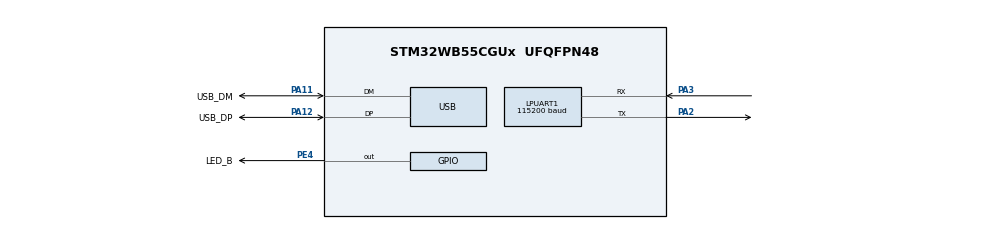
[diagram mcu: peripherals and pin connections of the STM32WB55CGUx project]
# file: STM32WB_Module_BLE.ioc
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Dma.LPUART1_RX.0.Direction=DMA_PERIPH_TO_MEMORY
Dma.LPUART1_RX.0.EventEnable=DISABLE
Dma.LPUART1_RX.0.Instance=DMA1_Channel1
Dma.LPUART1_RX.0.MemDataAlignment=DMA_MDATAALIGN_BYTE
Dma.LPUART1_RX.0.MemInc=DMA_MINC_ENABLE
Dma.LPUART1_RX.0.Mode=DMA_NORMAL
Dma.LPUART1_RX.0.PeriphDataAlignment=DMA_PDATAALIGN_BYTE
Dma.LPUART1_RX.0.PeriphInc=DMA_PINC_DISABLE
Dma.LPUART1_RX.0.Polarity=HAL_DMAMUX_REQ_GEN_RISING
Dma.LPUART1_RX.0.Priority=DMA_PRIORITY_MEDIUM
Dma.LPUART1_RX.0.RequestNumber=1
Dma.LPUART1_RX.0.SignalID=NONE
Dma.LPUART1_RX.0.SyncEnable=DISABLE
Dma.LPUART1_RX.0.SyncPolarity=HAL_DMAMUX_SYNC_NO_EVENT
Dma.LPUART1_RX.0.SyncRequestNumber=1
Dma.LPUART1_RX.0.SyncSignalID=NONE
Dma.LPUART1_TX.1.Direction=DMA_MEMORY_TO_PERIPH
Dma.LPUART1_TX.1.EventEnable=DISABLE
Dma.LPUART1_TX.1.Instance=DMA1_Channel2
Dma.LPUART1_TX.1.MemDataAlignment=DMA_MDATAALIGN_BYTE
Dma.LPUART1_TX.1.MemInc=DMA_MINC_ENABLE
Dma.LPUART1_TX.1.Mode=DMA_NORMAL
Dma.LPUART1_TX.1.PeriphDataAlignment=DMA_PDATAALIGN_BYTE
Dma.LPUART1_TX.1.PeriphInc=DMA_PINC_DISABLE
Dma.LPUART1_TX.1.Polarity=HAL_DMAMUX_REQ_GEN_RISING
Dma.LPUART1_TX.1.Priority=DMA_PRIORITY_MEDIUM
Dma.LPUART1_TX.1.RequestNumber=1
Dma.LPUART1_TX.1.SignalID=NONE
Dma.LPUART1_TX.1.SyncEnable=DISABLE
Dma.LPUART1_TX.1.SyncPolarity=HAL_DMAMUX_SYNC_NO_EVENT
Dma.LPUART1_TX.1.SyncRequestNumber=1
Dma.LPUART1_TX.1.SyncSignalID=NONE
Dma.Request0=LPUART1_RX
Dma.Request1=LPUART1_TX
LPUART1.BaudRate=115200
Mcu.Family=STM32WB
Mcu.Name=STM32WB55CGUx
Mcu.Package=UFQFPN48
NVIC.DMA1_Channel1_IRQn=true\:0\:0\:false\:false\:true\:false\:true\:true
NVIC.DMA1_Channel2_IRQn=true\:0\:0\:false\:false\:true\:false\:true\:true
NVIC.HSEM_IRQn=true\:0\:0\:false\:false\:true\:false\:true\:true
NVIC.IPCC_C1_RX_IRQn=true\:0\:0\:false\:false\:true\:true\:true\:true
NVIC.IPCC_C1_TX_IRQn=true\:0\:0\:false\:false\:true\:true\:true\:true
NVIC.LPUART1_IRQn=true\:0\:0\:false\:false\:true\:true\:true\:true
NVIC.PriorityGroup=NVIC_PRIORITYGROUP_4
NVIC.USB_HP_IRQn=true\:0\:0\:false\:false\:true\:true\:true\:true
NVIC.USB_LP_IRQn=true\:0\:0\:false\:false\:true\:false\:true\:true
OSC_IN.GPIO_Label=RCC_OSC_IN
OSC_IN.Mode=HSE-External-Oscillator
OSC_IN.Signal=RCC_OSC_IN
OSC_OUT.GPIO_Label=RCC_OSC_OUT
OSC_OUT.Mode=HSE-External-Oscillator
OSC_OUT.Signal=RCC_OSC_OUT
P-NUCLEO-WB55-USBDONGLE.BUTTON=1
P-NUCLEO-WB55-USBDONGLE.Bsp_Common_DEMO=true
P-NUCLEO-WB55-USBDONGLE.LD1=true
P-NUCLEO-WB55-USBDONGLE.LD2=true
P-NUCLEO-WB55-USBDONGLE.LD3=true
P-NUCLEO-WB55-USBDONGLE.VCP=false
PA11.GPIO_Label=USB_DM
PA11.Mode=Device
PA11.Signal=USB_DM
PA12.GPIO_Label=USB_DP
PA12.Mode=Device
PA12.Signal=USB_DP
PA13.GPIO_Label=JTMS
PA13.Signal=SYS_JTMS-SWDIO
PA14.GPIO_Label=JTCK
PA14.Signal=SYS_JTCK-SWCLK
PA2.Mode=Asynchronous
PA2.Signal=LPUART1_TX
PA3.Mode=Asynchronous
PA3.Signal=LPUART1_RX
PB3.GPIO_Label=JTDO
PB3.Signal=SYS_JTDO-SWO
PC14-OSC32_IN.GPIO_Label=RCC_OSC32_IN
PC14-OSC32_IN.Mode=LSE-External-Oscillator
PC14-OSC32_IN.Signal=RCC_OSC32_IN
PC15-OSC32_OUT.GPIO_Label=RCC_OSC32_OUT
PC15-OSC32_OUT.Mode=LSE-External-Oscillator
PC15-OSC32_OUT.Signal=RCC_OSC32_OUT
PE4.GPIO_Label=LED_B
PE4.Signal=GPIO_Output
ProjectManager.HeapSize=0x2000
ProjectManager.StackSize=0x4000
ProjectManager.TargetToolchain=CMake
RCC.ADCFreq_Value=48000000
RCC.AHB2CLKDivider=RCC_SYSCLK_DIV2
RCC.AHBFreq_Value=64000000
RCC.APB1Freq_Value=64000000
RCC.APB1TimFreq_Value=64000000
RCC.APB2Freq_Value=64000000
RCC.APB2TimFreq_Value=64000000
RCC.APB3Freq_Value=16000000
RCC.CK48CLockSelection=RCC_USBCLKSOURCE_PLL
RCC.CortexFreq_Value=64000000
RCC.HCLKFreq_Value=64000000
RCC.HSE_VALUE=32000000
RCC.HSI48_VALUE=48000000
RCC.HSI_VALUE=16000000
RCC.PLLN=48
RCC.PLLQ=RCC_PLLQ_DIV4
RCC.PLLR=RCC_PLLR_DIV3
RCC.PLLSAI1N=24
RCC.RTCClockSelection=RCC_RTCCLKSOURCE_LSE
RCC.SMPSDivider=1
RCC.SYSCLKFreq_VALUE=64000000
RCC.SYSCLKSource=RCC_SYSCLKSOURCE_PLLCLK
RCC.USBFreq_Value=48000000
RCC.VCOOutputFreq_Value=192000000
RF1.Mode=RF1_Activate
RF1.Signal=RF_RF1
STM32_WPAN.BLE_APPLICATION_TYPE=BLE_CLIENT_PROFILE
STM32_WPAN.CFG_BLE_NUM_LINK=8
STM32_WPAN.CFG_DEBUG_APP_TRACE=1
STM32_WPAN.CFG_DEBUG_TRACE_FULL=1
STM32_WPAN.CFG_DEBUG_TRACE_LIGHT=1
STM32_WPAN.CFG_DEBUG_TRACE_UART=hw_lpuart1
STM32_WPAN.CFG_HW_LPUART1_ENABLED=1
STM32_WPAN.CFG_LSCLK_LSE=0
USB_DEVICE.CLASS_NAME_FS=CDC
USB_DEVICE.VirtualMode=Cdc
USB_DEVICE.VirtualModeFS=Cdc_FS
VP_HSEM_VS_HSEM.Mode=HSEM_Activate
VP_IPCC_VS_IPCC.Mode=IPCC_Activate
VP_MEMORYMAP_VS_MEMORYMAP.Mode=CurAppReg
VP_RCC_USB.Mode=CRS SYNC Source USB
VP_RNG_VS_RNG.Mode=RNG_Activate
VP_RTC_VS_RTC_Activate.Mode=RTC_Enabled
VP_SEQUENCER_VS_SEQUENCER.Mode=SEQUENCER_Enabled
VP_STM32_WPAN_VS_BLE_HOST.Mode=STM32_WPAN_Enabled
VP_TINY_LPM_VS_TINY_LPM.Mode=TINY_LPM_Enabled
VP_USB_DEVICE_VS_USB_DEVICE_CDC_FS.Mode=CDC_FS
board=P-NUCLEO-WB55-USBDONGLE

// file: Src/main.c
/* USER CODE BEGIN Header */
/**
  ******************************************************************************
  * @file           : main.c
  * @brief          : Main program body
  ******************************************************************************
  * @attention
  *
  * Copyright (c) 2026 STMicroelectronics.
  * All rights reserved.
  *
  * This software is licensed under terms that can be found in the LICENSE file
  * in the root directory of this software component.
  * If no LICENSE file comes with this software, it is provided AS-IS.
  *
  ******************************************************************************
  */
/* USER CODE END Header */
#include "main.h"
#include "usb_device.h"

/* USER CODE BEGIN Includes */
#include "usbd_cdc_if.h"
#include "module_execute.h"
#include "at_command.h"
/* USER CODE END Includes */

IPCC_HandleTypeDef hipcc;

UART_HandleTypeDef hlpuart1;
DMA_HandleTypeDef hdma_lpuart1_rx;
DMA_HandleTypeDef hdma_lpuart1_tx;

RNG_HandleTypeDef hrng;

RTC_HandleTypeDef hrtc;

void SystemClock_Config(void);
void PeriphCommonClock_Config(void);
static void MX_GPIO_Init(void);
static void MX_DMA_Init(void);
static void MX_IPCC_Init(void);
static void MX_LPUART1_UART_Init(void);
static void MX_RTC_Init(void);
static void MX_RNG_Init(void);
static void MX_RF_Init(void);

/* USER CODE BEGIN 0 */
int _write(int file, char *ptr, int len)
{
  CDC_Transmit_FS((uint8_t *)ptr, len);
  // HAL_UART_Transmit(&hlpuart1, (uint8_t *)ptr, len, 0xFFFF);
  return len;
}
/* USER CODE END 0 */

int main(void)
{

  /* MCU Configuration--------------------------------------------------------*/

  /* Reset of all peripherals, Initializes the Flash interface and the Systick. */
  HAL_Init();
  /* Config code for STM32_WPAN (HSE Tuning must be done before system clock configuration) */
  MX_APPE_Config();

  /* Configure the system clock */
  SystemClock_Config();

  /* Configure the peripherals common clocks */
  PeriphCommonClock_Config();

  /* IPCC initialisation */
  MX_IPCC_Init();

  /* Initialize all configured peripherals */
  MX_GPIO_Init();
  MX_DMA_Init();
  MX_LPUART1_UART_Init();
  MX_RTC_Init();
  MX_RNG_Init();
  /* Init code for STM32_WPAN */
  MX_APPE_Init();
  HAL_Delay(100); // Delay to ensure BLE stack is properly initialized
  MX_USB_Device_Init();
  MX_RF_Init();
  /* USER CODE BEGIN 2 */
  printf("STM32WB55 BLE Gateway Starting...\r\n");
  HAL_GPIO_TogglePin(LED_B_GPIO_Port, LED_B_Pin);
  printf("Leds On\r\n");
  module_ble_init();
  printf("BLE Module Initialized\r\n");
  /* USER CODE END 2 */

  /* Infinite loop */
  while (1)
  {
    MX_APPE_Process();

  }
}

void SystemClock_Config(void)
{
  RCC_OscInitTypeDef RCC_OscInitStruct = {0};
  RCC_ClkInitTypeDef RCC_ClkInitStruct = {0};
  RCC_CRSInitTypeDef RCC_CRSInitStruct = {0};

  /** Configure LSE Drive Capability
  */
  HAL_PWR_EnableBkUpAccess();
  __HAL_RCC_LSEDRIVE_CONFIG(RCC_LSEDRIVE_MEDIUMHIGH);

  /** Configure the main internal regulator output voltage
  */
  __HAL_PWR_VOLTAGESCALING_CONFIG(PWR_REGULATOR_VOLTAGE_SCALE1);

  /** Initializes the RCC Oscillators according to the specified parameters
  * in the RCC_OscInitTypeDef structure.
  */
  RCC_OscInitStruct.OscillatorType = RCC_OSCILLATORTYPE_HSI|RCC_OSCILLATORTYPE_LSI1
                              |RCC_OSCILLATORTYPE_HSE|RCC_OSCILLATORTYPE_LSE
                              |RCC_OSCILLATORTYPE_MSI;
  RCC_OscInitStruct.HSEState = RCC_HSE_ON;
  RCC_OscInitStruct.LSEState = RCC_LSE_ON;
  RCC_OscInitStruct.HSIState = RCC_HSI_ON;
  RCC_OscInitStruct.MSIState = RCC_MSI_ON;
  RCC_OscInitStruct.HSICalibrationValue = RCC_HSICALIBRATION_DEFAULT;
  RCC_OscInitStruct.MSICalibrationValue = RCC_MSICALIBRATION_DEFAULT;
  RCC_OscInitStruct.MSIClockRange = RCC_MSIRANGE_6;
  RCC_OscInitStruct.LSIState = RCC_LSI_ON;
  RCC_OscInitStruct.PLL.PLLState = RCC_PLL_ON;
  RCC_OscInitStruct.PLL.PLLSource = RCC_PLLSOURCE_MSI;
  RCC_OscInitStruct.PLL.PLLM = RCC_PLLM_DIV1;
  RCC_OscInitStruct.PLL.PLLN = 48;
  RCC_OscInitStruct.PLL.PLLP = RCC_PLLP_DIV2;
  RCC_OscInitStruct.PLL.PLLR = RCC_PLLR_DIV3;
  RCC_OscInitStruct.PLL.PLLQ = RCC_PLLQ_DIV4;
  if (HAL_RCC_OscConfig(&RCC_OscInitStruct) != HAL_OK)
  {
    Error_Handler();
  }

  /** Configure the SYSCLKSource, HCLK, PCLK1 and PCLK2 clocks dividers
  */
  RCC_ClkInitStruct.ClockType = RCC_CLOCKTYPE_HCLK4|RCC_CLOCKTYPE_HCLK2
                              |RCC_CLOCKTYPE_HCLK|RCC_CLOCKTYPE_SYSCLK
                              |RCC_CLOCKTYPE_PCLK1|RCC_CLOCKTYPE_PCLK2;
  RCC_ClkInitStruct.SYSCLKSource = RCC_SYSCLKSOURCE_PLLCLK;
  RCC_ClkInitStruct.AHBCLKDivider = RCC_SYSCLK_DIV1;
  RCC_ClkInitStruct.APB1CLKDivider = RCC_HCLK_DIV1;
  RCC_ClkInitStruct.APB2CLKDivider = RCC_HCLK_DIV1;
  RCC_ClkInitStruct.AHBCLK2Divider = RCC_SYSCLK_DIV2;
  RCC_ClkInitStruct.AHBCLK4Divider = RCC_SYSCLK_DIV1;

  if (HAL_RCC_ClockConfig(&RCC_ClkInitStruct, FLASH_LATENCY_3) != HAL_OK)
  {
    Error_Handler();
  }

  /** Enable MSI Auto calibration
  */
  HAL_RCCEx_EnableMSIPLLMode();

  /** Enable the SYSCFG APB clock
  */
  __HAL_RCC_CRS_CLK_ENABLE();

  /** Configures CRS
  */
  RCC_CRSInitStruct.Prescaler = RCC_CRS_SYNC_DIV1;
  RCC_CRSInitStruct.Source = RCC_CRS_SYNC_SOURCE_USB;
  RCC_CRSInitStruct.Polarity = RCC_CRS_SYNC_POLARITY_RISING;
  RCC_CRSInitStruct.ReloadValue = __HAL_RCC_CRS_RELOADVALUE_CALCULATE(48000000,1000);
  RCC_CRSInitStruct.ErrorLimitValue = 34;
  RCC_CRSInitStruct.HSI48CalibrationValue = 32;

  HAL_RCCEx_CRSConfig(&RCC_CRSInitStruct);
}

void PeriphCommonClock_Config(void)
{
  RCC_PeriphCLKInitTypeDef PeriphClkInitStruct = {0};

  /** Initializes the peripherals clock
  */
  PeriphClkInitStruct.PeriphClockSelection = RCC_PERIPHCLK_SMPS|RCC_PERIPHCLK_RFWAKEUP;
  PeriphClkInitStruct.RFWakeUpClockSelection = RCC_RFWKPCLKSOURCE_HSE_DIV1024;
  PeriphClkInitStruct.SmpsClockSelection = RCC_SMPSCLKSOURCE_HSI;
  PeriphClkInitStruct.SmpsDivSelection = RCC_SMPSCLKDIV_RANGE0;

  if (HAL_RCCEx_PeriphCLKConfig(&PeriphClkInitStruct) != HAL_OK)
  {
    Error_Handler();
  }
}

static void MX_IPCC_Init(void)
{

  hipcc.Instance = IPCC;
  if (HAL_IPCC_Init(&hipcc) != HAL_OK)
  {
    Error_Handler();
  }

}

static void MX_LPUART1_UART_Init(void)
{

  hlpuart1.Instance = LPUART1;
  hlpuart1.Init.BaudRate = 115200;
  hlpuart1.Init.WordLength = UART_WORDLENGTH_8B;
  hlpuart1.Init.StopBits = UART_STOPBITS_1;
  hlpuart1.Init.Parity = UART_PARITY_NONE;
  hlpuart1.Init.Mode = UART_MODE_TX_RX;
  hlpuart1.Init.HwFlowCtl = UART_HWCONTROL_NONE;
  hlpuart1.Init.OneBitSampling = UART_ONE_BIT_SAMPLE_DISABLE;
  hlpuart1.Init.ClockPrescaler = UART_PRESCALER_DIV1;
  hlpuart1.AdvancedInit.AdvFeatureInit = UART_ADVFEATURE_NO_INIT;
  hlpuart1.FifoMode = UART_FIFOMODE_DISABLE;
  if (HAL_UART_Init(&hlpuart1) != HAL_OK)
  {
    Error_Handler();
  }
  if (HAL_UARTEx_SetTxFifoThreshold(&hlpuart1, UART_TXFIFO_THRESHOLD_1_8) != HAL_OK)
  {
    Error_Handler();
  }
  if (HAL_UARTEx_SetRxFifoThreshold(&hlpuart1, UART_RXFIFO_THRESHOLD_1_8) != HAL_OK)
  {
    Error_Handler();
  }
  if (HAL_UARTEx_DisableFifoMode(&hlpuart1) != HAL_OK)
  {
    Error_Handler();
  }
  /* USER CODE BEGIN LPUART1_Init 2 */
  __HAL_UART_ENABLE_IT(&hlpuart1, UART_IT_RXNE);
  HAL_NVIC_SetPriority(LPUART1_IRQn, 5, 0);
  HAL_NVIC_EnableIRQ(LPUART1_IRQn);
  /* USER CODE END LPUART1_Init 2 */

}

static void MX_RF_Init(void)
{

}

static void MX_RNG_Init(void)
{

  hrng.Instance = RNG;
  hrng.Init.ClockErrorDetection = RNG_CED_ENABLE;
  if (HAL_RNG_Init(&hrng) != HAL_OK)
  {
    Error_Handler();
  }

}

static void MX_RTC_Init(void)
{

  /** Initialize RTC Only
  */
  hrtc.Instance = RTC;
  hrtc.Init.HourFormat = RTC_HOURFORMAT_24;
  hrtc.Init.AsynchPrediv = CFG_RTC_ASYNCH_PRESCALER;
  hrtc.Init.SynchPrediv = CFG_RTC_SYNCH_PRESCALER;
  hrtc.Init.OutPut = RTC_OUTPUT_DISABLE;
  hrtc.Init.OutPutPolarity = RTC_OUTPUT_POLARITY_HIGH;
  hrtc.Init.OutPutType = RTC_OUTPUT_TYPE_OPENDRAIN;
  hrtc.Init.OutPutRemap = RTC_OUTPUT_REMAP_NONE;
  if (HAL_RTC_Init(&hrtc) != HAL_OK)
  {
    Error_Handler();
  }

}

static void MX_DMA_Init(void)
{

  /* DMA controller clock enable */
  __HAL_RCC_DMAMUX1_CLK_ENABLE();
  __HAL_RCC_DMA1_CLK_ENABLE();

  /* DMA interrupt init */
  /* DMA1_Channel1_IRQn interrupt configuration */
  HAL_NVIC_SetPriority(DMA1_Channel1_IRQn, 0, 0);
  HAL_NVIC_EnableIRQ(DMA1_Channel1_IRQn);
  /* DMA1_Channel2_IRQn interrupt configuration */
  HAL_NVIC_SetPriority(DMA1_Channel2_IRQn, 0, 0);
  HAL_NVIC_EnableIRQ(DMA1_Channel2_IRQn);

}

static void MX_GPIO_Init(void)
{
  GPIO_InitTypeDef GPIO_InitStruct = {0};

  /* GPIO Ports Clock Enable */
  __HAL_RCC_GPIOC_CLK_ENABLE();
  __HAL_RCC_GPIOA_CLK_ENABLE();
  __HAL_RCC_GPIOE_CLK_ENABLE();
  __HAL_RCC_GPIOB_CLK_ENABLE();

  /*Configure GPIO pin Output Level */
  HAL_GPIO_WritePin(LED_B_GPIO_Port, LED_B_Pin, GPIO_PIN_RESET);

  /*Configure GPIO pin : LED_B_Pin */
  GPIO_InitStruct.Pin = LED_B_Pin;
  GPIO_InitStruct.Mode = GPIO_MODE_OUTPUT_PP;
  GPIO_InitStruct.Pull = GPIO_NOPULL;
  GPIO_InitStruct.Speed = GPIO_SPEED_FREQ_LOW;
  HAL_GPIO_Init(LED_B_GPIO_Port, &GPIO_InitStruct);

}

void Error_Handler(void)
{
  __disable_irq();
  while (1)
  {
  }
}
